# myChip register map
Vendor: ARM Ltd.; Series: ARMCM3; File version: 1.2
ARM 32-bit Cortex-M3 Microcontroller based device, CPU clock up to 80MHz, etc.
CPU: CM3 r2p1, little endian, no MPU, no FPU, 3 interrupt priority bits
Registers are 32-bit, read-write, reset 0x0 unless marked. A register's access mark holds for its fields unless they carry their own. Offsets are from the block's base; lines under a group give offsets from that group; [hi:lo] are bit positions; {n}, {i} and the like mark numbered series; 'fields as' and 'values as' point back to an identical list; <NAME> marks a mode.

## Memory map
0x40000000 I2C0 size 0x1000
0x40001000 I2C1 size 0x1000
0x40002000 I2C2 size 0x1000
0x40003000 UART0 size 0x1000
0x40004000 UART1 size 0x1000
0x40005000 UART2 size 0x1000
0x40008000 TMR7 size 0x1000
0x40009000 TMR8 size 0x1000
0x4000C000 IWDG size 0x1000
0x4000D000 WWDG size 0x1000
0x4000E000 TMR6 size 0x1000
0x40010000 UART3 size 0x1000
0x40011000 UART4 size 0x1000
0x40012000 SPI0 size 0x1000
0x40013000 SPI1 size 0x1000
0x40014000 CAN0 size 0x1000
0x40015000 CAN1 size 0x1000
0x40016000 XIF size 0x1000
0x40017000 PDM0 size 0x1000
0x40017100 PDM1 size 0x1000
0x40017200 PDM2 size 0x1000
0x40017300 PDM3 size 0x1000
0x40018000 TMR0 size 0x1000
0x40019000 TMR1 size 0x1000
0x4001A000 TMR2 size 0x1000
0x40020000 RCU size 0x1000
0x40021000 SYSCTRL size 0x1000
0x40022000 DMA0 size 0x1000
0x40022020 DMA1 size 0x1000
0x40022040 DMA2 size 0x1000
0x40022060 DMA3 size 0x1000
0x40022080 DMA4 size 0x1000
0x400220A0 DMA5 size 0x1000
0x40023000 FLASH size 0x1000
0x40024000 GPIOA size 0x1000
0x40025000 GPIOB size 0x1000
0x40026000 GPIOC size 0x1000
0x40027000 GPIOD size 0x1000
0x40028000 GPIOE size 0x1000
0x40029000 GPIOF size 0x1000
0x4002A000 TMR3 size 0x1000
0x4002B000 TMR4 size 0x1000
0x4002D000 QEI0 size 0x1000
0x4002E000 QEI1 size 0x1000
0x4002F000 QEI2 size 0x1000
0x40030000 TMR9 size 0x1000
0x40031000 TMR10 size 0x1000
0x40035000 USB size 0x1000
0x40038000 ADC0 size 0x1000
0x40038400 ADC1 size 0x1000
0x40038800 ADC2 size 0x1000
0x40038C00 ADC3 size 0x1000
{0x40039000+0x100*n} DAC{n} size 0x1000 (n=0..8)
{0x4003A000+0x100*n} CMP{n} size 0x1000 (n=0..8)
0x4003B000 HRPWM_MST size 0x1000
{0x4003B100+0x100*n} HRPWM_SLV{n} size 0x1000 (n=0..7)
0x4003BF00 HRPWM_COM size 0x1000
0x4003E000 IIR0 size 0x1000
0x4003E100 IIR1 size 0x1000
0x4003E200 IIR2 size 0x1000
0x4003E300 IIR3 size 0x1000
0x4003E400 IIR4 size 0x1000
0x4003E500 IIR5 size 0x1000
0x4003F000 CORDIC size 0x1000

## Interrupts
0 I2C0
1 I2C1
2 I2C2
3 UART0
4 UART1
5 UART2
6 UART3
7 UART4
8 SPI0
9 SPI1
10 CAN0
11 CAN1
12 PDM0
13 PDM1
14 PDM2
15 PDM3
16 QEI0
17 QEI1
18 QEI2
19 DMA_CH0 (DMA0)
20 DMA_CH1 (DMA1)
21 DMA_CH2 (DMA2)
22 DMA_CH3 (DMA3)
23 DMA_CH4 (DMA4)
24 DMA_CH5 (DMA5)
25 TMR7
26 TMR8
27 TMR0
28 TMR1
29 TMR2
30 TMR3
31 TMR4
32 TMR9_BRK (TMR9)
33 TMR9_UPD (TMR9)
34 TMR9_TRG (TMR9)
35 TMR9_CC (TMR9)
36 TMR10_BRK (TMR10)
37 TMR10_UPD (TMR10)
38 TMR10_TRG (TMR10)
39 TMR10_CC (TMR10)
40 IWDG
41 WWDG
42 GPIOA
43 GPIOB
44 GPIOC
45 GPIOD
46 GPIOE
47 GPIOF
48 FLASH
49 IIR (IIR{n} (n=0..5)) — IIR0_5 Interrupt Group
50 CORDIC
51 CMPG0 (CMP{n} (n=0..2)) — CMP0_2 Interrupt Group
52 CMPG1 (CMP{n} (n=3..5)) — CMP3_5 Interrupt Group
53 CMPG2 (CMP{n} (n=6..8)) — CMP6_8 Interrupt Group
54 HRPWM_MST
{n+55} HRPWM_SLV{n} (n=0..7)
63 HRPWM_COM
64 ADC0_NORM (ADC0)
65 ADC0_SAMP (ADC0)
66 ADC0_HALF (ADC0)
67 ADC0_FULL (ADC0)
68 ADC1_NORM (ADC1)
69 ADC1_SAMP (ADC1)
70 ADC1_HALF (ADC1)
71 ADC1_FULL (ADC1)
72 ADC2_NORM (ADC2)
73 ADC2_SAMP (ADC2)
74 ADC2_HALF (ADC2)
75 ADC2_FULL (ADC2)
76 ADC3_NORM (ADC3)
77 ADC3_SAMP (ADC3)
78 ADC3_HALF (ADC3)
79 ADC3_FULL (ADC3)
80 PMU (SYSCTRL)
81 USB_PWR (USB)
82 USB_DET (USB)
83 USB_EP (USB)
84 XIF
85 CAN0_INT1 (CAN0)
86 CAN1_INT1 (CAN1)
87 TMR6

## XIF
Base 0x40016000
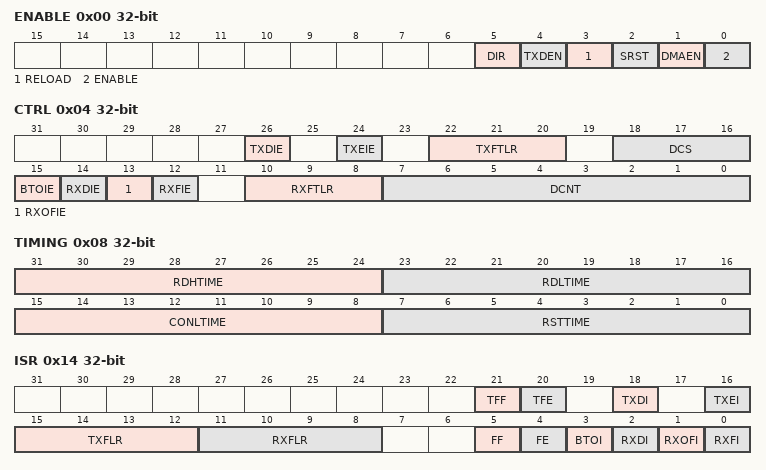
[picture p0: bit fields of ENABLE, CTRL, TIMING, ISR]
0x00 ENABLE — XIF Enable Register
  [5] DIR — XIF传输方向（XIF Transfer Direction）
  [4] TXDEN — XIF DMA发送使能（XIF DMA Enable）
  [3] RELOAD — 重复模式（Reload Mode）
  [2] SRST — XIF软复位（XIF Software Reset）
  [1] DMAEN — XIF DMA接收使能（XIF DMA Enable）
  [0] ENABLE — XIF使能（XIF Enable）
0x04 CTRL — XIF Control Register
  [26] TXDIE — TXDI中断使能（XIF Tx Done Interrupt Enable）
  [24] TXEIE — TXEI中断使能（TXFIFO Empty Interrupt Enable）
  [22:20] TXFTLR — TXFIFO空中断阈值（TXFIFO Empty Watermark）
  [18:16] DCS — XIF采样时间点延后选择（XIF Delay Chain Select）
  [15] BTOIE — BTOI中断使能（XIF Wait BUSY Timeout Interrupt Enable）
  [14] RXDIE — RXDI中断使能（XIF Rx Done Interrupt Enable）
  [13] RXOFIE — RXOFI中断使能（RXFIFO Overflow Interrupt Enable）
  [12] RXFIE — RXFI中断使能（RXFIFO Full Interrupt Enable）
  [10:8] RXFTLR — RXFIFO满中断阈值（RXFIFO Full Watermark）
  [7:0] DCNT — XIF传输数据量（The Count of DATA）
0x08 TIMING — XIF Timing Register
  [31:24] RDHTIME — XIF RD为高的时间长度（The Length Of Time For RD High）
  [23:16] RDLTIME — XIF RD为低的时间长度（The Length Of Time For RD Low）
  [15:8] CONLTIME — XIF CONVST为低的时间长度（The Length Of Time For CONVST Low）
  [7:0] RSTTIME — XIF RESET为高的时间长度（The Length Of Time For RESET High）
0x0C TO — XIF Timeout Register
  [15:0] PTOT — XIF超时设置（XIF BUSY TIMEOUT Timing）
0x10 DATA — XIF Read Data Registers
  [15:0] DATA ro — 读取数据寄存器（FIFO Read DATA Register）
0x14 ISR — XIF Interrupt And Status Register
  [21] TFF ro — TXFIFO满标志（TXFIFO Full Flag）
  [20] TFE ro — TXFIFO空标志（TXFIFO Empty Flag）
  [18] TXDI — XIF发送完成中断（XIF TX Done Interrupt）
  [16] TXEI ro — TXFIFO空中断（TXFIFO Empty Interrupt）
  [15:12] TXFLR ro — TXFIFO实时剩余数据量（TXFIFO Level Register）
  [11:8] RXFLR ro — RXFIFO实时剩余数据量（RXFIFO Level Register）
  [5] FF ro — RXFIFO满标志（RXFIFO Full Flag）
  [4] FE ro — RXFIFO空标志（RXFIFO Empty Flag）
  [3] BTOI — XIF等待BUSY超时中断（XIF Wait BUSY Timeout Interrupt Enable）
  [2] RXDI — XIF接收完成中断（XIF RX Done Interrupt）
  [1] RXOFI — RXFIFO上溢中断（RXFIFO Overflow Interrupt）
  [0] RXFI ro — RXFIFO满中断（RXFIFO Full Interrupt）
0x18 WDATA — XIF Write Data Registers
  [15:0] WDATA — 写入数据寄存器（FIFO Write DATA Register）
